# SAMA7D65D2GN8 register map
Vendor: Microchip Technology; Series: SAMA7D6; File version: 0
Registers are 32-bit, read-write, reset 0x0 unless marked. A register's access mark holds for its fields unless they carry their own. Offsets are from the block's base; [hi:lo] are bit positions; {n}, {i} and the like mark numbered series.

## PDMC0 — Pulse Density Microphone Controller
Base 0xE2800000; register names take the prefix PDMC_
Same registers: PDMC1 0xE2804000
0x00 CR wo — Control Register
  [0] SWRST — Software Reset
    0=No effect; 1=Resets the PDMC interface
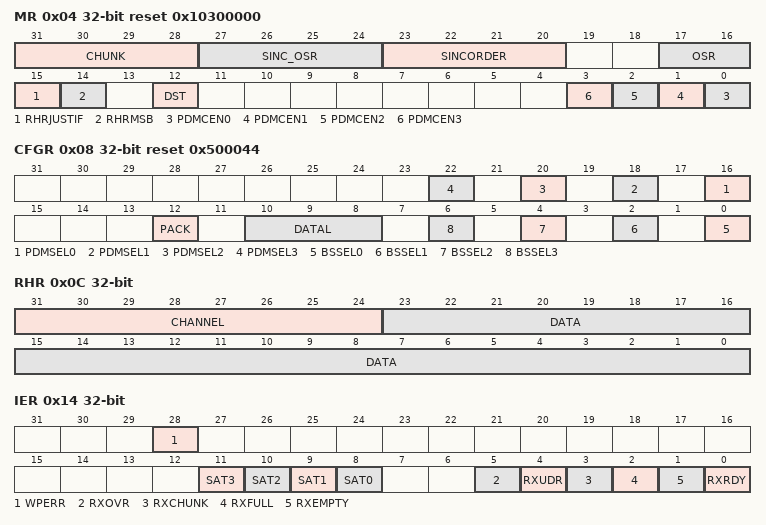
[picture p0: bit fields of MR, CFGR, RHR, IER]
0x04 MR reset 0x10300000 — Mode Register
  [31:28] CHUNK — Chunk Size
  [27:24] SINC_OSR — SINC Filter Oversampling Ratio
    0=DISABLE (Audio filtering mode. The SINC filter OSR is implicitly defined by the PDMC_MR.OSR field.); 1=OSR8 (The SINC filter OSR is 8.); 2=OSR16 (The SINC filter OSR is 16.); 3=OSR32 (The SINC filter OSR is 32.); 4=OSR64 (The SINC filter OSR is 64.); 5=OSR128 (The SINC filter OSR is 128.); 6=OSR256 (The SINC filter OSR is 256.)
  [23:20] SINCORDER — SINC Filter Order
    1=ORDER1 (SINC filter order is 1.); 2=ORDER2 (SINC filter order is 2.); 3=ORDER3 (SINC filter order is 3. Recommended if SINC_OSR=0); 4=ORDER4 (SINC filter order is 4.); 5=ORDER5 (SINC filter order is 5.)
  [17:16] OSR — Audio Oversampling Ratio
    1=OSR is 64; 2=OSR is 128; 3=OSR is 256
  [15] RHRJUSTIF — RHR Justification Mode
    0=RIGHT (The audio sample data is right-justified in PDMC_RHR.); 1=LEFT (The audio sample data is left-justified in PDMC_RHR.)
  [14] RHRMSB — RHR MSB Mode
    0=CH_INDEX (The MSB section of PDMC_RHR contains the index of the microphone channel where the audio data sample.); 1=ZERO_OR_DATA (When RHRJUSTIF=0, the MSB section of PDMC_RHR contains the sign extension. PDMC_RHR carries the audio samples of all the enabled channels in a round robin manner.)
  [12] DST — Audio Data Destination
    0=DMA_SOFT (Audio data are read through PDMC_RHR by the DMA or software.); 1=DIRECT_TO_ASRC (Audio data are transferred directly to the ASRC without DMA intervention or software.)
  [n] PDMCEN{n} (n=0..3) — PDMC Channel {n} Enable
    0=DISABLE (PDMC is disabled.); 1=ENABLE (PDMC is enabled.)
0x08 CFGR reset 0x500044 — Configuration Register
  [2n+16] PDMSEL{n} (n=0..3) — PDM Microphone Source Selection
    0=DS0 (PDMSELx corresponds to PMDC_DS0.); 1=DS1 (PDMSELx corresponds to PMDC_DS1.)
  [12] PACK — Packed Data
    0=Data are not packed; 1=Data are packed (if the DATAL configuration allows packing)
  [10:8] DATAL — Data Length
    0=24_BITS (Data are defined on 24 bits.); 1=32_BITS (Data are defined on 32 bits.); 2=20_BITS (Data are defined on 20 bits.); 3=16_BITS (Data are defined on 16 bits.); 4=8_BITS (Data are defined on 8 bits.)
  [2n] BSSEL{n} (n=0..3) — Bitstream Source Selection
    0=The selected PDMC_DSx source is sampled on the positive edge of PDMC_CLK; 1=The selected PDMC_DSx source is sampled on the negative edge of PDMC_CLK
0x0C RHR ro — Receive Holding Register
  [31:24] CHANNEL — Channel Index of Data
  [23:0] DATA — Converted Data
0x14 IER wo — Interrupt Enable Register
  [28] WPERR — Write Protect Event Interrupt Enable
  [n+8] SAT{n} (n=0..3) — Saturation Detection on Channel {n} Interrupt Enable
  [5] RXOVR — Receive Over Flow Interrupt Enable
  [4] RXUDR — Receive Under Flow Interrupt Enable
  [3] RXCHUNK — Receive FIFO Chunk Interrupt Enable
  [2] RXFULL — Receive FIFO Full Interrupt Enable
  [1] RXEMPTY — Receive FIFO Empty Interrupt Enable
  [0] RXRDY — Receive Ready Interrupt Enable
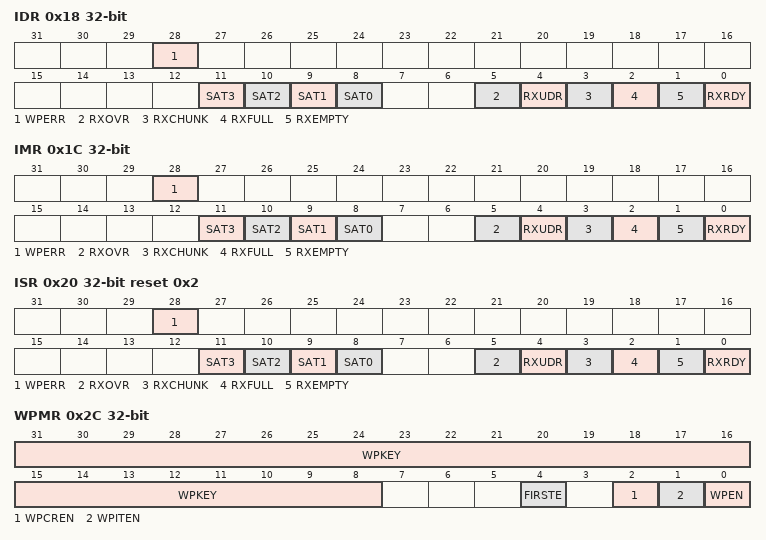
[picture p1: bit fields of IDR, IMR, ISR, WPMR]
0x18 IDR wo — Interrupt Disable Register
  [28] WPERR — Write Protect Event Interrupt Disable
  [n+8] SAT{n} (n=0..3) — Saturation Detection on Channel {n} Interrupt Disable
  [5] RXOVR — Receive Over Flow Interrupt Disable
  [4] RXUDR — Receive Under Flow Interrupt Disable
  [3] RXCHUNK — Receive FIFO Chunk Interrupt Disable
  [2] RXFULL — Receive FIFO Full Interrupt Disable
  [1] RXEMPTY — Receive FIFO Empty Interrupt Disable
  [0] RXRDY — Receive Ready Interrupt Disable
0x1C IMR ro — Interrupt Mask Register
  [28] WPERR — Write Protect Event Interrupt Mask
  [n+8] SAT{n} (n=0..3) — Saturation Detection on Channel {n} Interrupt Mask
  [5] RXOVR — Receive Over Flow Interrupt Mask
  [4] RXUDR — Receive Under Flow Interrupt Mask
  [3] RXCHUNK — Receive FIFO Chunk Interrupt Mask
  [2] RXFULL — Receive FIFO Full Interrupt Mask
  [1] RXEMPTY — Receive FIFO Empty Interrupt Mask
  [0] RXRDY — Receive Ready Interrupt Mask
0x20 ISR ro reset 0x2 — Interrupt Status Register
  [28] WPERR — Write Protect Event Interrupt Status (cleared on read)
    0=No security event has occurred since the last read of PDMC_ISR; 1=One or more security events occurred since the last read of PDMC_ISR. For details on the event(s), see PDMC Write Protection Status Register.
  [n+8] SAT{n} (n=0..3) — Saturation Detection on Channel {n} Interrupt Status (cleared on read)
    0=No saturation event has occurred on channel x since the last read of PDMC_ISR; 1=One or more saturation event has occurred on channel x since the last read of PDMC_ISR
  [5] RXOVR — Receive Over Flow Interrupt Status (cleared on read)
    0=No overflow event occurred since the last read of PDMC_ISR; 1=At least one overflow event occurred since the last read of PDMC_ISR
  [4] RXUDR — Receive Under Flow Interrupt Status (cleared on read)
    0=No underflow event occurred since the last read of PDMC_ISR; 1=At least one underflow event occurred since the last read of PDMC_ISR
  [3] RXCHUNK — Receive FIFO Chunk Interrupt Status (cleared by reading PDMC_RHR)
    0=There is less than PDMC_MR.CHUNK data in the RX FIFO; 1=At least PDMC_MR.CHUNK data can be read in the RX FIFO
  [2] RXFULL — Receive FIFO Full Interrupt Status (cleared by reading PDMC_RHR)
    0=The RX FIFO is not full and can still receive data; 1=The RX FIFO is full and cannot receive more data
  [1] RXEMPTY — Receive FIFO Empty Interrupt Status (automatically cleared when an audio sample is generated)
    0=At least one data is in the RX FIFO; 1=The RX FIFO is empty
  [0] RXRDY — Receive Ready Interrupt Status (cleared by reading PDMC_RHR)
    0=There is no data in the RX FIFO; 1=At least one data is in the RX FIFO and can be read through PDMC_RHR
0x2C WPMR — Write Protection Mode Register
  [31:8] WPKEY — Write Protection Key
    0x50444D=PASSWD (Writing any other value in this field aborts the write operation of the WPEN and WPITEN bits. Always read at 0.)
  [4] FIRSTE — First Error Report Enable
    0=The last write protection violation source is reported in PDMC_WPSR.WPSRC and the last software control error type is reported in PDMC_WPSR.SWETYP. The PDMC_ISR.WPERR flag is set at the first error occurrence within a series.; 1=Only the first write protection violation source is reported in PDMC_WPSR.WPSRC and only the first software control error type is reported in PDMC_WPSR.SWETYP. The PDMC_ISR.WPERR flag is set at the first error occurrence within a series.
  [2] WPCREN — Write Protection Enable for Control Register
    0=Disables the write protection on control registers if WPKEY corresponds to 0x50444D ('PDM' in ASCII); 1=Enables the write protection on control registers if WPKEY corresponds to 0x50444D ('PDM' in ASCII)
  [1] WPITEN — Write Protection Enable for Interrupt
    0=Disables the write protection on interrupt registers if WPKEY corresponds to 0x50444D ('PDM' in ASCII); 1=Enables the write protection on interrupt registers if WPKEY corresponds to 0x50444D ('PDM' in ASCII)
  [0] WPEN — Write Protection Enable for Configuration Registers
    0=Disables write protection if WPKEY corresponds to 0x50444D ('PDM' in ASCII); 1=Enables write protection if WPKEY corresponds to 0x50444D ('PDM' in ASCII)
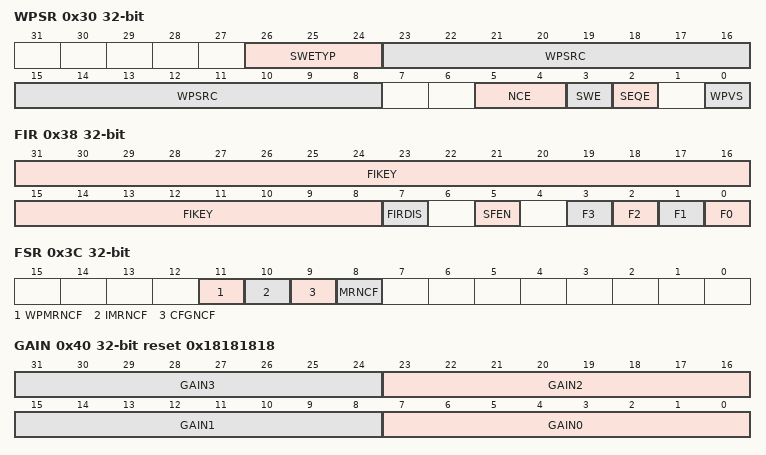
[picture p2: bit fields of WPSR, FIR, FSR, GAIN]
0x30 WPSR ro — Write Protection Status Register
  [26:24] SWETYP — Software Error Type (cleared on read)
    0=READ_WO (A write-only register has been read.); 1=WRITE_RO (A write access has been performed on a read-only register.); 2=UNDEF_RW (Access to an undefined address.)
  [23:8] WPSRC — Write Protection Source
  [5:4] NCE — Non-Corrected Error (cleared by reconfiguring the faulty registers)
    0=No error is detected in the configuration registers
  [3] SWE — Software Control Error (cleared on read)
    0=No software error has occurred since the last read of PDMC_WPSR; 1=A software error has occurred since the last read of PDMC_WPSR. SWETYP provides details on the type of software error. The associated incorrect software access is reported in WPSRC (if WPVS=0).
  [2] SEQE — Internal Sequencer Error (cleared on read)
    0=No peripheral internal sequencer error has occurred since the last read of PDMC_WPSR; 1=A peripheral internal sequencer error has occurred since the last read of PDMC_WPSR
  [0] WPVS — Write Protection Violation Status (cleared on read)
    0=No write protection violation has occurred since the last read of PDMC_WPSR; 1=A write protection violation has occurred since the last read of PDMC_WPSR. If this violation is an unauthorized attempt to write a protected register, the associated violation is reported into the field WPSRC.
0x38 FIR — Fault Injection Register
  [31:8] FIKEY — Fault Injection Key (read only)
    0x504649=PASSWD (Writing any other value in this field aborts the write operation. Always reads as 0.)
  [7] FIRDIS — Fault Injection Register Disable
    0=NO_EFFECT; 1=ACTIVE (Disables the fault injection until the next hardware reset. The command is valid only if PDMC_WPSR.NCE=0 and the other bits are cleared (F0=F1=F2=F3=SFEN=0).)
  [5] SFEN — Single Fault Enable
  [3] F3 — Single Fault for Write Protection Mode Register (PDMC_WPMR)
    0=No effect; 1=Creates a single fault in the error detection circuitry of PDMC_WPMR (the configuration is not modified) which triggers PDMC_WPSR.NCE to '3'
  [2] F2 — Single Fault for Interrupt Mask Register (PDMC_IMR)
    0=No effect; 1=Creates a single fault in the error detection circuitry of PDMC_IMR (the configuration is not modified) which triggers PDMC_WPSR.NCE to '3'
  [1] F1 — Single Fault for Configuration Register (PDMC_CFGR)
    0=No effect; 1=Creates a single fault in the error detection circuitry of PDMC_CFGR (the configuration is not modified) which triggers PDMC_WPSR.NCE to '3'
  [0] F0 — Single Fault for Mode Register (PDMC_MR)
    0=No effect; 1=Creates a single fault in the error detection circuitry of PDMC_MR (the configuration is not modified) which triggers PDMC_WPSR.NCE to '3'
0x3C FSR ro — Fault Status Register
  [11] WPMRNCF — Write Protection Mode Register Non-Corrected Fault Status
    0=No fault in PDMC_WPMR; 1=An error is detected in PDMC_WPMR. To correct the fault, write accesses must be performed in PDMC_WPMR with the correct value.
  [10] IMRNCF — User Data Registers Non-Corrected Fault Status
    0=No fault in PDMC_IMR; 1=An error is detected in PDMC_IMR. To correct the fault, a write access must be performed in PDMC_IDR to clear all the sources of interrupts and a write access must be performed in the PDMC_IER to reload the correct value for the enabled sources of interrupt.
  [9] CFGNCF — Configuration Register Non-Corrected Fault Status
    0=No fault in PDMC_CFGR; 1=An error is detected in PDMC_CFGR. To correct the fault, a write access must be performed in PDMC_CFGR with the correct value.
  [8] MRNCF — Mode Registers Non-Corrected Fault Status
    0=No fault in PDMC_MR; 1=An error is detected in PDMC_MR. To correct the fault, a write access must be performed in PDMC_MR with the correct value.
0x40 GAIN reset 0x18181818
  [8n+7:8n] GAIN{n} (n=0..3) — Gain of Channel {n}
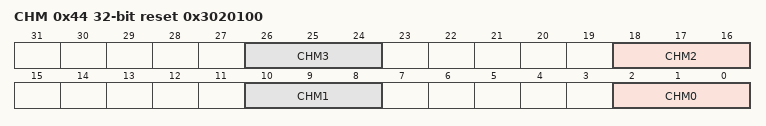
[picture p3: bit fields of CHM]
0x44 CHM reset 0x3020100 — Channel Mapping Register
  [8n+2:8n] CHM{n} (n=0..3) — Channel Mapping {n}
